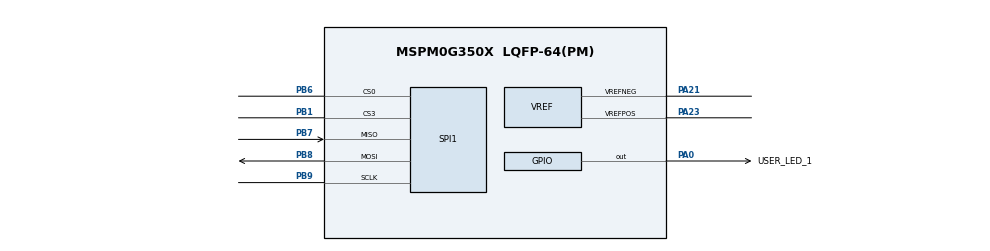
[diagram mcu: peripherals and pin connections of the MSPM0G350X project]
/**
 * @cliArgs --device "MSPM0G350X" --package "LQFP-64(PM)" --part "Default" --product "mspm0_sdk@2.01.00.03"
 * @versions {"tool":"1.20.0+3587"}
 */

/**
 * Import the modules used in this configuration.
 */
const ADC12         = scripting.addModule("/ti/driverlib/ADC12", {}, false);
const ADC121        = ADC12.addInstance();
const Board         = scripting.addModule("/ti/driverlib/Board");
const COMP          = scripting.addModule("/ti/driverlib/COMP", {}, false);
const COMP1         = COMP.addInstance();
const DAC12         = scripting.addModule("/ti/driverlib/DAC12");
const GPIO          = scripting.addModule("/ti/driverlib/GPIO", {}, false);
const GPIO1         = GPIO.addInstance();
const GPIO2         = GPIO.addInstance();
const OPA           = scripting.addModule("/ti/driverlib/OPA", {}, false);
const OPA1          = OPA.addInstance();
const SPI           = scripting.addModule("/ti/driverlib/SPI", {}, false);
const SPI1          = SPI.addInstance();
const SYSCTL        = scripting.addModule("/ti/driverlib/SYSCTL");
const TIMER         = scripting.addModule("/ti/driverlib/TIMER", {}, false);
const TIMER1        = TIMER.addInstance();
const UART          = scripting.addModule("/ti/driverlib/UART", {}, false);
const UART1         = UART.addInstance();
const VREF          = scripting.addModule("/ti/driverlib/VREF");
const ProjectConfig = scripting.addModule("/ti/project_config/ProjectConfig");

/**
 * Write custom configuration values to the imported modules.
 */
const gate8  = system.clockTree["MFPCLKGATE"];
gate8.enable = true;

ADC121.$name                             = "ADC12_0";
ADC121.sampClkDiv                        = "DL_ADC12_CLOCK_DIVIDE_8";
ADC121.powerDownMode                     = "DL_ADC12_POWER_DOWN_MODE_MANUAL";
ADC121.trigSrc                           = "DL_ADC12_TRIG_SRC_EVENT";
ADC121.adcMem0chansel                    = "DL_ADC12_INPUT_CHAN_2";
ADC121.sampClkSrc                        = "DL_ADC12_CLOCK_ULPCLK";
ADC121.subChanID                         = 1;
ADC121.configureDMA                      = true;
ADC121.sampCnt                           = 1;
ADC121.enabledInterrupts                 = ["DL_ADC12_INTERRUPT_DMA_DONE"];
ADC121.interruptPriority                 = "1";
ADC121.enabledDMATriggers                = ["DL_ADC12_DMA_MEM0_RESULT_LOADED"];
ADC121.repeatMode                        = true;
ADC121.sampleTime0                       = "250 ns";
ADC121.adcMem0trig                       = "DL_ADC12_TRIGGER_MODE_TRIGGER_NEXT";
ADC121.peripheral.$assign                = "ADC0";
ADC121.adcPin2Config.$name               = "ti_driverlib_gpio_GPIOPinGeneric0";
ADC121.DMA_CHANNEL.$name                 = "DMA_CH0";
ADC121.DMA_CHANNEL.addressMode           = "f2b";
ADC121.DMA_CHANNEL.srcLength             = "HALF_WORD";
ADC121.DMA_CHANNEL.dstLength             = "HALF_WORD";
ADC121.DMA_CHANNEL.configureTransferSize = true;
ADC121.DMA_CHANNEL.transferSize          = 1024;


COMP1.$name         = "COMP_0";
COMP1.hysteresis    = "DL_COMP_HYSTERESIS_20";
COMP1.vSource       = "DL_COMP_REF_SOURCE_VDDA_DAC";
COMP1.controlSelect = "DL_COMP_DAC_CONTROL_SW";
COMP1.setDACCode0   = 0x4D;

DAC12.dacOutputPinEn     = true;
DAC12.dacAmplifier       = "ON";
DAC12.dacPosVREF         = "VEREFP";
DAC12.dacNegVREF         = "VEREFN";
DAC12.OutPinConfig.$name = "ti_driverlib_gpio_GPIOPinGeneric1";

GPIO1.$name                          = "GPIO_LEDS";
GPIO1.port                           = "PORTA";
GPIO1.portSegment                    = "Lower";
GPIO1.associatedPins[0].$name        = "USER_LED_1";
GPIO1.associatedPins[0].assignedPin  = "0";
GPIO1.associatedPins[0].initialValue = "SET";
GPIO1.associatedPins[0].pin.$assign  = "PA0";

GPIO2.port                           = "PORTA";
GPIO2.$name                          = "GPIO_OUTPUT";
GPIO2.associatedPins.create(2);
GPIO2.associatedPins[0].$name        = "DIODE";
GPIO2.associatedPins[1].$name        = "CS";
GPIO2.associatedPins[1].initialValue = "SET";

OPA1.$name              = "OPA_0";
OPA1.cfg0OutputPin      = "ENABLED";
OPA1.cfg0PSELChannel    = "DAC8_OUT";
OPA1.cfg0NSELChannel    = "RTOP";
OPA1.advBW              = "HIGH";
OPA1.peripheral.$assign = "OPA0";
OPA1.OutPinConfig.$name = "ti_driverlib_gpio_GPIOPinGeneric2";

SPI1.$name                      = "SPI_0";
SPI1.bitOrder                   = "LSB";
SPI1.targetBitRate              = 500000;
SPI1.enableCDMode               = true;
SPI1.peripheral.$assign         = "SPI1";
SPI1.peripheral.sclkPin.$assign = "PB9";
SPI1.peripheral.mosiPin.$assign = "PB8";
SPI1.peripheral.misoPin.$assign = "PB7";
SPI1.peripheral.cs0Pin.$assign  = "PB6";
SPI1.peripheral.cs3Pin.$assign  = "PB1";
SPI1.sclkPinConfig.$name        = "ti_driverlib_gpio_GPIOPinGeneric5";
SPI1.mosiPinConfig.$name        = "ti_driverlib_gpio_GPIOPinGeneric6";
SPI1.misoPinConfig.$name        = "ti_driverlib_gpio_GPIOPinGeneric7";
SPI1.cs0PinConfig.$name         = "ti_driverlib_gpio_GPIOPinGeneric8";
SPI1.cs3PinConfig.$name         = "ti_driverlib_gpio_GPIOPinGeneric9";

SYSCTL.forceDefaultClkConfig = true;
SYSCTL.clockTreeEn           = true;

TIMER1.$name                       = "TIMER_0";
TIMER1.timerMode                   = "PERIODIC";
TIMER1.event1PublisherChannel      = 1;
TIMER1.event1ControllerInterruptEn = ["ZERO_EVENT"];
TIMER1.counterZero                 = true;
TIMER1.timerStartTimer             = true;
TIMER1.timerPeriod                 = "1us";

UART1.$name             = "UART_0";
UART1.txPinConfig.$name = "ti_driverlib_gpio_GPIOPinGeneric10";
UART1.rxPinConfig.$name = "ti_driverlib_gpio_GPIOPinGeneric11";

VREF.basicIntVolt                  = "DL_VREF_BUFCONFIG_OUTPUT_2_5V";
VREF.checkVREFReady                = true;
VREF.advClockConfigEnable          = true;
VREF.advClkSrc                     = "DL_VREF_CLOCK_BUSCLK";
VREF.basicVrefPins                 = "VREF+-";
VREF.peripheral.$assign            = "VREF";
VREF.peripheral.vrefPosPin.$assign = "PA23";
VREF.peripheral.vrefNegPin.$assign = "PA21";
VREF.vrefPosPinConfig.$name        = "ti_driverlib_gpio_GPIOPinGeneric3";
VREF.vrefNegPinConfig.$name        = "ti_driverlib_gpio_GPIOPinGeneric4";

ProjectConfig.genLibCMSIS = true;

/**
 * Pinmux solution for unlocked pins/peripherals. This ensures that minor changes to the automatic solver in a future
 * version of the tool will not impact the pinmux you originally saw.  These lines can be completely deleted in order to
 * re-solve from scratch.
 */
ADC121.peripheral.adcPin2.$suggestSolution     = "PA25";
ADC121.DMA_CHANNEL.peripheral.$suggestSolution = "DMA_CH0";
Board.peripheral.$suggestSolution              = "DEBUGSS";
Board.peripheral.swclkPin.$suggestSolution     = "PA20";
Board.peripheral.swdioPin.$suggestSolution     = "PA19";
COMP1.peripheral.$suggestSolution              = "COMP0";
DAC12.peripheral.$suggestSolution              = "DAC0";
DAC12.peripheral.OutPin.$suggestSolution       = "PA15";
GPIO2.associatedPins[0].pin.$suggestSolution   = "PA13";
GPIO2.associatedPins[1].pin.$suggestSolution   = "PA12";
OPA1.peripheral.OutPin.$suggestSolution        = "PA22";
TIMER1.peripheral.$suggestSolution             = "TIMA0";
UART1.peripheral.$suggestSolution              = "UART0";
UART1.peripheral.rxPin.$suggestSolution        = "PA1";
UART1.peripheral.txPin.$suggestSolution        = "PA10";
